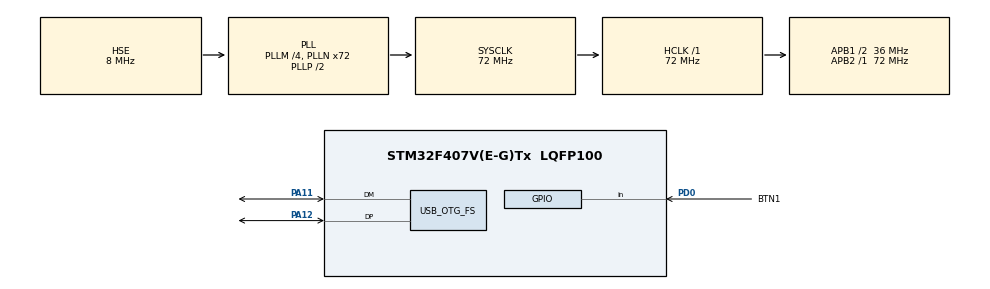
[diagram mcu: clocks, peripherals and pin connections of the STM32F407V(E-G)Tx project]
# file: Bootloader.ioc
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Mcu.Family=STM32F4
Mcu.Name=STM32F407V(E-G)Tx
Mcu.Package=LQFP100
NVIC.OTG_FS_IRQn=true\:0\:0\:false\:false\:true\:false\:true\:true
NVIC.PriorityGroup=NVIC_PRIORITYGROUP_4
PA11.Mode=Device_Only
PA11.Signal=USB_OTG_FS_DM
PA12.Mode=Device_Only
PA12.Signal=USB_OTG_FS_DP
PD0.GPIO_Label=BTN1
PD0.Signal=GPIO_Input
PH0-OSC_IN.Mode=HSE-External-Oscillator
PH0-OSC_IN.Signal=RCC_OSC_IN
PH1-OSC_OUT.Mode=HSE-External-Oscillator
PH1-OSC_OUT.Signal=RCC_OSC_OUT
ProjectManager.HeapSize=0x200
ProjectManager.StackSize=0x400
ProjectManager.TargetToolchain=CMake
RCC.48MHZClocksFreq_Value=48000000
RCC.AHBFreq_Value=72000000
RCC.APB1CLKDivider=RCC_HCLK_DIV2
RCC.APB1Freq_Value=36000000
RCC.APB1TimFreq_Value=72000000
RCC.APB2Freq_Value=72000000
RCC.APB2TimFreq_Value=72000000
RCC.CortexFreq_Value=72000000
RCC.HCLKFreq_Value=72000000
RCC.HSE_VALUE=8000000
RCC.HSI_VALUE=16000000
RCC.LSE_VALUE=32768
RCC.PLLM=4
RCC.PLLN=72
RCC.PLLQ=3
RCC.SYSCLKFreq_VALUE=72000000
RCC.SYSCLKSource=RCC_SYSCLKSOURCE_PLLCLK
RCC.VCOOutputFreq_Value=144000000
USB_DEVICE.CLASS_NAME_FS=DFU
USB_DEVICE.VirtualMode-DFU_FS=Dfu
USB_DEVICE.VirtualModeFS=Dfu_FS
USB_OTG_FS.VirtualMode=Device_Only
VP_USB_DEVICE_VS_USB_DEVICE_DFU_FS.Mode=DFU_FS
board=custom

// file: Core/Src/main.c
/* USER CODE BEGIN Header */
/**
  ******************************************************************************
  * @file           : main.c
  * @brief          : Main program body
  ******************************************************************************
  * @attention
  *
  * Copyright (c) 2026 STMicroelectronics.
  * All rights reserved.
  *
  * This software is licensed under terms that can be found in the LICENSE file
  * in the root directory of this software component.
  * If no LICENSE file comes with this software, it is provided AS-IS.
  *
  ******************************************************************************
  */
/* USER CODE END Header */
#include "main.h"
#include "usb_device.h"

/* USER CODE BEGIN Includes */
#include "boot.h"
/* USER CODE END Includes */

void SystemClock_Config(void);
static void MX_GPIO_Init(void);

int main(void)
{

  /* MCU Configuration--------------------------------------------------------*/

  /* Reset of all peripherals, Initializes the Flash interface and the Systick. */
  HAL_Init();

  /* Configure the system clock */
  SystemClock_Config();

  /* USER CODE BEGIN SysInit */
  if (Boot_EnterDfu() == 0)
  {
    Boot_JumpToApplication();
  }
  /* USER CODE END SysInit */

  /* Initialize all configured peripherals */
  MX_GPIO_Init();
  MX_USB_DEVICE_Init();

  /* Infinite loop */
  while (1)
  {

  }
}

void SystemClock_Config(void)
{
  RCC_OscInitTypeDef RCC_OscInitStruct = {0};
  RCC_ClkInitTypeDef RCC_ClkInitStruct = {0};

  /** Configure the main internal regulator output voltage
  */
  __HAL_RCC_PWR_CLK_ENABLE();
  __HAL_PWR_VOLTAGESCALING_CONFIG(PWR_REGULATOR_VOLTAGE_SCALE1);

  /** Initializes the RCC Oscillators according to the specified parameters
  * in the RCC_OscInitTypeDef structure.
  */
  RCC_OscInitStruct.OscillatorType = RCC_OSCILLATORTYPE_HSE;
  RCC_OscInitStruct.HSEState = RCC_HSE_ON;
  RCC_OscInitStruct.PLL.PLLState = RCC_PLL_ON;
  RCC_OscInitStruct.PLL.PLLSource = RCC_PLLSOURCE_HSE;
  RCC_OscInitStruct.PLL.PLLM = 4;
  RCC_OscInitStruct.PLL.PLLN = 72;
  RCC_OscInitStruct.PLL.PLLP = RCC_PLLP_DIV2;
  RCC_OscInitStruct.PLL.PLLQ = 3;
  if (HAL_RCC_OscConfig(&RCC_OscInitStruct) != HAL_OK)
  {
    Error_Handler();
  }

  /** Initializes the CPU, AHB and APB buses clocks
  */
  RCC_ClkInitStruct.ClockType = RCC_CLOCKTYPE_HCLK|RCC_CLOCKTYPE_SYSCLK
                              |RCC_CLOCKTYPE_PCLK1|RCC_CLOCKTYPE_PCLK2;
  RCC_ClkInitStruct.SYSCLKSource = RCC_SYSCLKSOURCE_PLLCLK;
  RCC_ClkInitStruct.AHBCLKDivider = RCC_SYSCLK_DIV1;
  RCC_ClkInitStruct.APB1CLKDivider = RCC_HCLK_DIV2;
  RCC_ClkInitStruct.APB2CLKDivider = RCC_HCLK_DIV1;

  if (HAL_RCC_ClockConfig(&RCC_ClkInitStruct, FLASH_LATENCY_2) != HAL_OK)
  {
    Error_Handler();
  }
}

static void MX_GPIO_Init(void)
{
  GPIO_InitTypeDef GPIO_InitStruct = {0};

  /* GPIO Ports Clock Enable */
  __HAL_RCC_GPIOH_CLK_ENABLE();
  __HAL_RCC_GPIOA_CLK_ENABLE();
  __HAL_RCC_GPIOD_CLK_ENABLE();

  /*Configure GPIO pin : BTN1_Pin */
  GPIO_InitStruct.Pin = BTN1_Pin;
  GPIO_InitStruct.Mode = GPIO_MODE_INPUT;
  GPIO_InitStruct.Pull = GPIO_NOPULL;
  HAL_GPIO_Init(BTN1_GPIO_Port, &GPIO_InitStruct);

}

void Error_Handler(void)
{
  __disable_irq();
  while (1)
  {
  }
}
